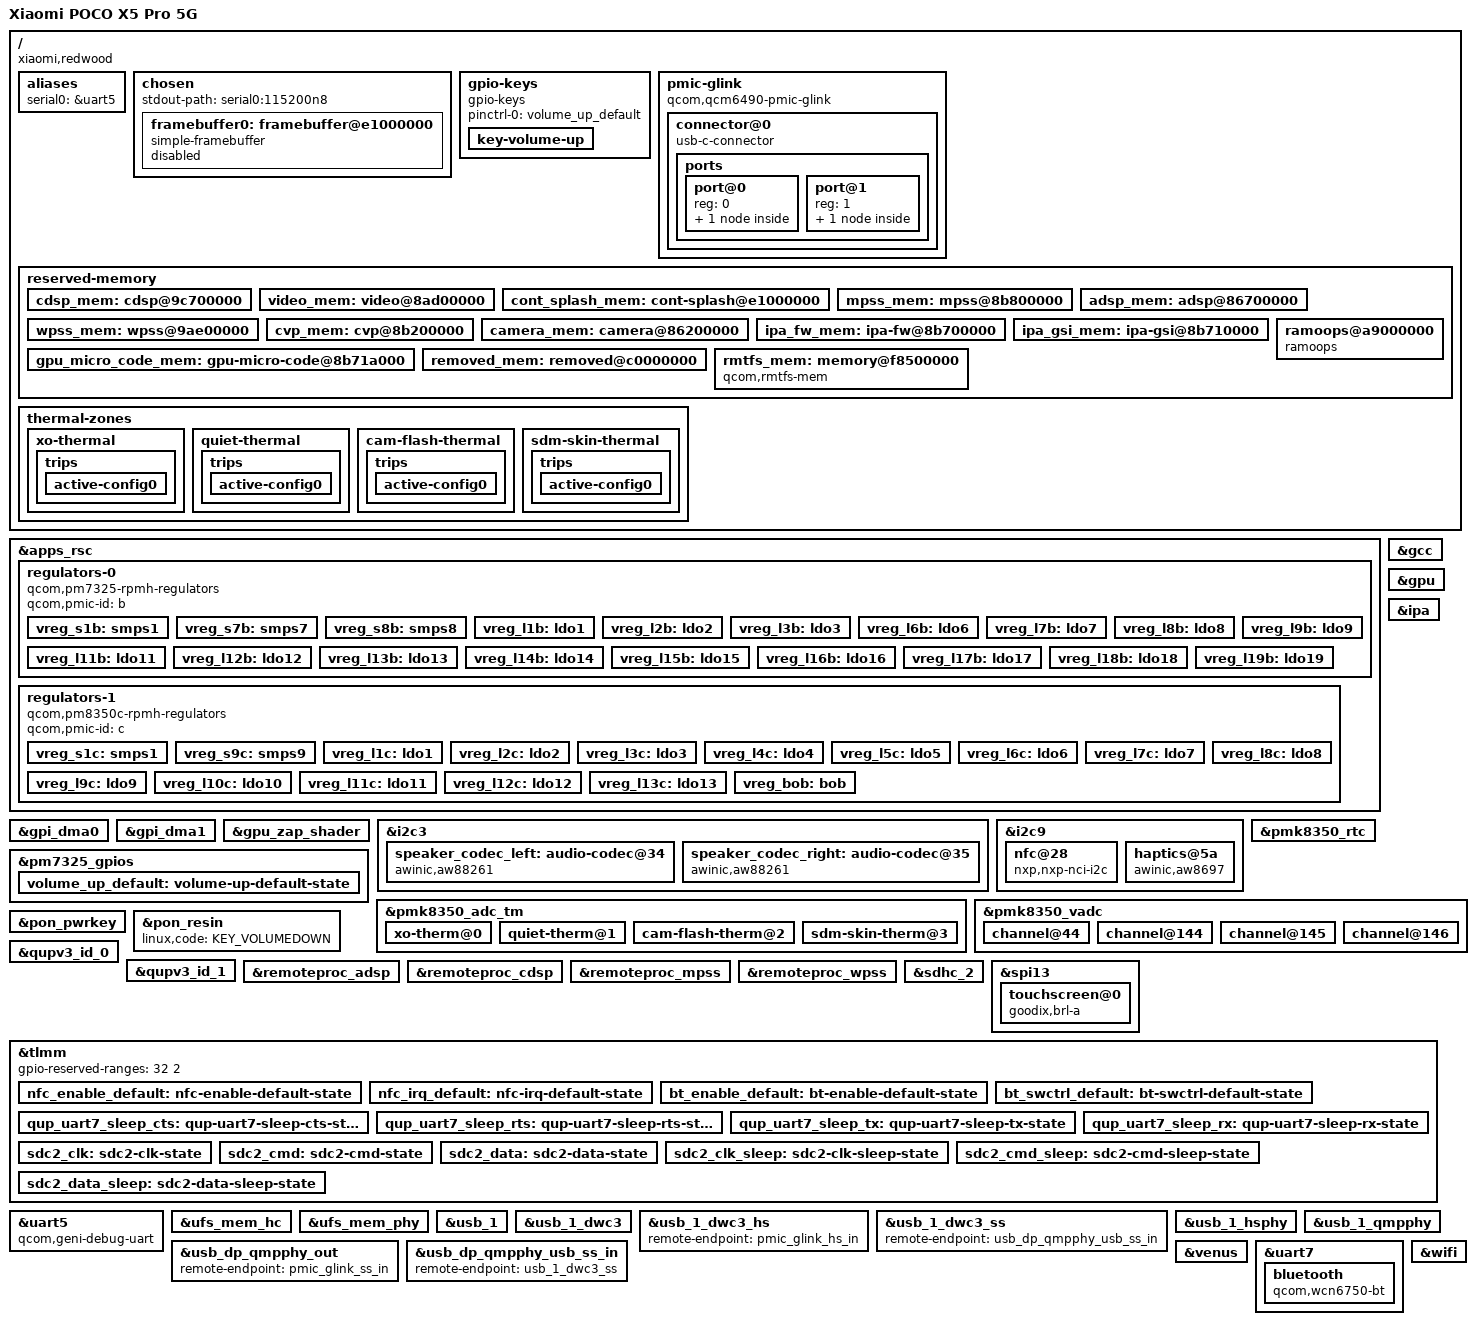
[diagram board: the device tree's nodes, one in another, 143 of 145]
// SPDX-License-Identifier: BSD-3-Clause
/*
 * Copyright (c) 2024, Gianluca Boiano
 *
 * Based on qcm6490-fairphone-fp5.dts
 */

/dts-v1/;

#include <dt-bindings/arm/qcom,ids.h>
#include <dt-bindings/gpio/gpio.h>
#include <dt-bindings/iio/qcom,spmi-adc7-pm7325.h>
#include <dt-bindings/iio/qcom,spmi-adc7-pmk8350.h>
#include <dt-bindings/input/input.h>
#include <dt-bindings/pinctrl/qcom,pmic-gpio.h>
#include <dt-bindings/regulator/qcom,rpmh-regulator.h>
#include "sc7280.dtsi"
#include "pm7325.dtsi"
#include "pm8350c.dtsi"
#include "pmk8350.dtsi"

/delete-node/ &rmtfs_mem;

/ {
	model = "Xiaomi POCO X5 Pro 5G";
	compatible = "xiaomi,redwood", "qcom,sm7325";
	chassis-type = "handset";

	/* SM7325 msm-id: 475 (0x1db) and 515 (0x203) */
	qcom,msm-id = <QCOM_ID_SM7325 0x10000>,
		      <QCOM_ID_SM7325P 0x10000>;
	qcom,board-id = <0x1000b 0x0>;

	aliases {
		serial0 = &uart5;
	};

	chosen {
		#address-cells = <2>;
		#size-cells = <2>;
		ranges;

		stdout-path = "serial0:115200n8";

		framebuffer0: framebuffer@e1000000 {
			compatible = "simple-framebuffer";
			reg = <0x0 0xe1000000 0x0 (1080 * 2400 * 4)>;
			width = <1080>;
			height = <2400>;
			stride = <(1080 * 4)>;
			format = "a8r8g8b8";
			status = "disabled";
		};
	};

	gpio-keys {
		compatible = "gpio-keys";

		pinctrl-0 = <&volume_up_default>;
		pinctrl-names = "default";

		key-volume-up {
			label = "Volume up";
			gpios = <&pm7325_gpios 6 GPIO_ACTIVE_LOW>;
			linux,code = <KEY_VOLUMEUP>;
			debounce-interval = <15>;
		};
	};

	pmic-glink {
		compatible = "qcom,qcm6490-pmic-glink", "qcom,pmic-glink";

		#address-cells = <1>;
		#size-cells = <0>;

		connector@0 {
			compatible = "usb-c-connector";
			reg = <0>;
			power-role = "dual";
			data-role = "dual";

			ports {
				#address-cells = <1>;
				#size-cells = <0>;

				port@0 {
					reg = <0>;

					pmic_glink_hs_in: endpoint {
						remote-endpoint = <&usb_1_dwc3_hs>;
					};
				};

				port@1 {
					reg = <1>;

					pmic_glink_ss_in: endpoint {
						remote-endpoint = <&usb_dp_qmpphy_out>;
					};
				};
			};
		};
	};

	reserved-memory {
		/* Override cdsp_mem from sc7280.dtsi with SM7325 address */
		/delete-node/ cdsp@88f00000;
		cdsp_mem: cdsp@9c700000 {
			reg = <0x0 0x9c700000 0x0 0x1e00000>;
			no-map;
		};

		/* Override video_mem from sc7280.dtsi with SM7325 address */
		/delete-node/ video@8b200000;
		video_mem: video@8ad00000 {
			reg = <0x0 0x8ad00000 0x0 0x500000>;
			no-map;
		};

		cont_splash_mem: cont-splash@e1000000 {
			reg = <0x0 0xe1000000 0x0 0x2300000>;
			no-map;
		};

		mpss_mem: mpss@8b800000 {
			reg = <0x0 0x8b800000 0x0 0xf600000>;
			no-map;
		};

		adsp_mem: adsp@86700000 {
			reg = <0x0 0x86700000 0x0 0x4000000>;
			no-map;
		};

		wpss_mem: wpss@9ae00000 {
			reg = <0x0 0x9ae00000 0x0 0x1900000>;
			no-map;
		};

		cvp_mem: cvp@8b200000 {
			reg = <0x0 0x8b200000 0x0 0x500000>;
			no-map;
		};

		camera_mem: camera@86200000 {
			reg = <0x0 0x86200000 0x0 0x500000>;
			no-map;
		};

		ipa_fw_mem: ipa-fw@8b700000 {
			reg = <0x0 0x8b700000 0x0 0x10000>;
			no-map;
		};

		ipa_gsi_mem: ipa-gsi@8b710000 {
			reg = <0x0 0x8b710000 0x0 0xa000>;
			no-map;
		};

		gpu_micro_code_mem: gpu-micro-code@8b71a000 {
			reg = <0x0 0x8b71a000 0x0 0x2000>;
			no-map;
		};

		removed_mem: removed@c0000000 {
			reg = <0x0 0xc0000000 0x0 0x6800000>;
			no-map;
		};

		rmtfs_mem: memory@f8500000 {
			compatible = "qcom,rmtfs-mem";
			reg = <0x0 0xf8500000 0x0 0x600000>;
			no-map;

			qcom,client-id = <1>;
			qcom,vmid = <QCOM_SCM_VMID_MSS_MSA>, <QCOM_SCM_VMID_NAV>;
		};

		ramoops@a9000000 {
			compatible = "ramoops";
			reg = <0x0 0xa9000000 0x0 0x200000>;
			pmsg-size = <0x200000>;
			console-size = <0x100000>;
		};
	};

	thermal-zones {
		xo-thermal {
			polling-delay-passive = <0>;
			polling-delay = <0>;
			thermal-sensors = <&pmk8350_adc_tm 0>;

			trips {
				active-config0 {
					temperature = <125000>;
					hysteresis = <1000>;
					type = "passive";
				};
			};
		};

		quiet-thermal {
			polling-delay-passive = <0>;
			polling-delay = <0>;
			thermal-sensors = <&pmk8350_adc_tm 1>;

			trips {
				active-config0 {
					temperature = <125000>;
					hysteresis = <1000>;
					type = "passive";
				};
			};
		};

		cam-flash-thermal {
			polling-delay-passive = <0>;
			polling-delay = <0>;
			thermal-sensors = <&pmk8350_adc_tm 2>;

			trips {
				active-config0 {
					temperature = <125000>;
					hysteresis = <1000>;
					type = "passive";
				};
			};
		};

		sdm-skin-thermal {
			polling-delay-passive = <0>;
			polling-delay = <0>;
			thermal-sensors = <&pmk8350_adc_tm 3>;

			trips {
				active-config0 {
					temperature = <125000>;
					hysteresis = <1000>;
					type = "passive";
				};
			};
		};
	};
};

&apps_rsc {
	regulators-0 {
		compatible = "qcom,pm7325-rpmh-regulators";
		qcom,pmic-id = "b";

		vreg_s1b: smps1 {
			regulator-min-microvolt = <1840000>;
			regulator-max-microvolt = <2040000>;
		};

		vreg_s7b: smps7 {
			regulator-min-microvolt = <535000>;
			regulator-max-microvolt = <1120000>;
		};

		vreg_s8b: smps8 {
			regulator-min-microvolt = <1200000>;
			regulator-max-microvolt = <1500000>;
			regulator-initial-mode = <RPMH_REGULATOR_MODE_RET>;
		};

		vreg_l1b: ldo1 {
			regulator-min-microvolt = <825000>;
			regulator-max-microvolt = <925000>;
			regulator-initial-mode = <RPMH_REGULATOR_MODE_HPM>;
		};

		vreg_l2b: ldo2 {
			regulator-min-microvolt = <2700000>;
			regulator-max-microvolt = <3544000>;
			regulator-initial-mode = <RPMH_REGULATOR_MODE_HPM>;
		};

		vreg_l3b: ldo3 {
			regulator-min-microvolt = <312000>;
			regulator-max-microvolt = <910000>;
			regulator-initial-mode = <RPMH_REGULATOR_MODE_HPM>;
		};

		vreg_l6b: ldo6 {
			regulator-min-microvolt = <1140000>;
			regulator-max-microvolt = <1260000>;
			regulator-initial-mode = <RPMH_REGULATOR_MODE_HPM>;
		};

		vreg_l7b: ldo7 {
			regulator-min-microvolt = <2952000>;
			regulator-max-microvolt = <2952000>;
			regulator-initial-mode = <RPMH_REGULATOR_MODE_HPM>;
		};

		vreg_l8b: ldo8 {
			regulator-min-microvolt = <870000>;
			regulator-max-microvolt = <970000>;
			regulator-initial-mode = <RPMH_REGULATOR_MODE_HPM>;
		};

		vreg_l9b: ldo9 {
			regulator-min-microvolt = <1200000>;
			regulator-max-microvolt = <1304000>;
			regulator-initial-mode = <RPMH_REGULATOR_MODE_HPM>;
		};

		vreg_l11b: ldo11 {
			regulator-min-microvolt = <1504000>;
			regulator-max-microvolt = <2000000>;
			regulator-initial-mode = <RPMH_REGULATOR_MODE_HPM>;
		};

		vreg_l12b: ldo12 {
			regulator-min-microvolt = <751000>;
			regulator-max-microvolt = <824000>;
			regulator-initial-mode = <RPMH_REGULATOR_MODE_HPM>;
		};

		vreg_l13b: ldo13 {
			regulator-min-microvolt = <530000>;
			regulator-max-microvolt = <824000>;
			regulator-initial-mode = <RPMH_REGULATOR_MODE_HPM>;
		};

		vreg_l14b: ldo14 {
			regulator-min-microvolt = <1080000>;
			regulator-max-microvolt = <1304000>;
			regulator-initial-mode = <RPMH_REGULATOR_MODE_HPM>;
		};

		vreg_l15b: ldo15 {
			regulator-min-microvolt = <765000>;
			regulator-max-microvolt = <1020000>;
			regulator-initial-mode = <RPMH_REGULATOR_MODE_HPM>;
		};

		vreg_l16b: ldo16 {
			regulator-min-microvolt = <1100000>;
			regulator-max-microvolt = <1300000>;
			regulator-initial-mode = <RPMH_REGULATOR_MODE_HPM>;
		};

		vreg_l17b: ldo17 {
			regulator-min-microvolt = <1700000>;
			regulator-max-microvolt = <1900000>;
			regulator-initial-mode = <RPMH_REGULATOR_MODE_HPM>;
		};

		vreg_l18b: ldo18 {
			regulator-min-microvolt = <1800000>;
			regulator-max-microvolt = <2000000>;
			regulator-initial-mode = <RPMH_REGULATOR_MODE_HPM>;
		};

		vreg_l19b: ldo19 {
			regulator-min-microvolt = <1800000>;
			regulator-max-microvolt = <2000000>;
			regulator-initial-mode = <RPMH_REGULATOR_MODE_HPM>;
		};
	};

	regulators-1 {
		compatible = "qcom,pm8350c-rpmh-regulators";
		qcom,pmic-id = "c";

		vreg_s1c: smps1 {
			regulator-min-microvolt = <2190000>;
			regulator-max-microvolt = <2210000>;
			regulator-initial-mode = <RPMH_REGULATOR_MODE_HPM>;
		};

		vreg_s9c: smps9 {
			regulator-min-microvolt = <1010000>;
			regulator-max-microvolt = <1170000>;
			regulator-initial-mode = <RPMH_REGULATOR_MODE_HPM>;
		};

		vreg_l1c: ldo1 {
			regulator-min-microvolt = <1800000>;
			regulator-max-microvolt = <1980000>;
			regulator-initial-mode = <RPMH_REGULATOR_MODE_HPM>;
		};

		vreg_l2c: ldo2 {
			regulator-min-microvolt = <1800000>;
			regulator-max-microvolt = <1950000>;
			regulator-initial-mode = <RPMH_REGULATOR_MODE_HPM>;
		};

		vreg_l3c: ldo3 {
			regulator-min-microvolt = <3000000>;
			regulator-max-microvolt = <3400000>;
			regulator-initial-mode = <RPMH_REGULATOR_MODE_HPM>;
		};

		vreg_l4c: ldo4 {
			regulator-min-microvolt = <1620000>;
			regulator-max-microvolt = <3300000>;
			regulator-initial-mode = <RPMH_REGULATOR_MODE_HPM>;
		};

		vreg_l5c: ldo5 {
			regulator-min-microvolt = <1620000>;
			regulator-max-microvolt = <3300000>;
			regulator-initial-mode = <RPMH_REGULATOR_MODE_HPM>;
		};

		vreg_l6c: ldo6 {
			regulator-min-microvolt = <1650000>;
			regulator-max-microvolt = <3544000>;
			regulator-initial-mode = <RPMH_REGULATOR_MODE_HPM>;
		};

		vreg_l7c: ldo7 {
			regulator-min-microvolt = <3000000>;
			regulator-max-microvolt = <3544000>;
			regulator-initial-mode = <RPMH_REGULATOR_MODE_HPM>;
		};

		vreg_l8c: ldo8 {
			regulator-min-microvolt = <1620000>;
			regulator-max-microvolt = <2000000>;
			regulator-initial-mode = <RPMH_REGULATOR_MODE_HPM>;
		};

		vreg_l9c: ldo9 {
			regulator-min-microvolt = <2700000>;
			regulator-max-microvolt = <3544000>;
			regulator-initial-mode = <RPMH_REGULATOR_MODE_HPM>;
		};

		vreg_l10c: ldo10 {
			regulator-min-microvolt = <720000>;
			regulator-max-microvolt = <1050000>;
			regulator-initial-mode = <RPMH_REGULATOR_MODE_HPM>;
		};

		vreg_l11c: ldo11 {
			regulator-min-microvolt = <2800000>;
			regulator-max-microvolt = <3544000>;
			regulator-initial-mode = <RPMH_REGULATOR_MODE_HPM>;
		};

		vreg_l12c: ldo12 {
			regulator-min-microvolt = <1650000>;
			regulator-max-microvolt = <2000000>;
			regulator-initial-mode = <RPMH_REGULATOR_MODE_HPM>;
		};

		vreg_l13c: ldo13 {
			regulator-min-microvolt = <2700000>;
			regulator-max-microvolt = <3544000>;
			regulator-initial-mode = <RPMH_REGULATOR_MODE_HPM>;
		};

		vreg_bob: bob {
			regulator-min-microvolt = <3008000>;
			regulator-max-microvolt = <3960000>;
			regulator-initial-mode = <RPMH_REGULATOR_MODE_AUTO>;
		};
	};
};

&gcc {
	protected-clocks = <GCC_CFG_NOC_LPASS_CLK>,
			   <GCC_EDP_CLKREF_EN>,
			   <GCC_MSS_CFG_AHB_CLK>,
			   <GCC_MSS_GPLL0_MAIN_DIV_CLK_SRC>,
			   <GCC_MSS_OFFLINE_AXI_CLK>,
			   <GCC_MSS_Q6SS_BOOT_CLK_SRC>,
			   <GCC_MSS_Q6_MEMNOC_AXI_CLK>,
			   <GCC_MSS_SNOC_AXI_CLK>,
			   <GCC_QSPI_CNOC_PERIPH_AHB_CLK>,
			   <GCC_QSPI_CORE_CLK>,
			   <GCC_QSPI_CORE_CLK_SRC>,
			   <GCC_SEC_CTRL_CLK_SRC>,
			   <GCC_WPSS_AHB_BDG_MST_CLK>,
			   <GCC_WPSS_AHB_CLK>,
			   <GCC_WPSS_RSCP_CLK>;
};

&gpi_dma0 {
	status = "okay";
};

&gpi_dma1 {
	status = "okay";
};

&gpu {
	status = "okay";
};

&gpu_zap_shader {
	firmware-name = "qcom/sm7325/xiaomi/redwood/a660_zap.mbn";
};

&i2c3 {
	status = "okay";

	/* Awinic AW882XX stereo amplifiers */
	speaker_codec_left: audio-codec@34 {
		compatible = "awinic,aw88261";
		reg = <0x34>;
		#sound-dai-cells = <0>;
		awinic,audio-channel = <1>;
		awinic,sync-flag;
	};

	speaker_codec_right: audio-codec@35 {
		compatible = "awinic,aw88261";
		reg = <0x35>;
		#sound-dai-cells = <0>;
		awinic,audio-channel = <0>;
		awinic,sync-flag;
	};
};

&i2c9 {
	status = "okay";

	/* NXP SN100/SN110 NFC Controller */
	nfc@28 {
		compatible = "nxp,nxp-nci-i2c";
		reg = <0x28>;

		interrupt-parent = <&tlmm>;
		interrupts = <41 IRQ_TYPE_LEVEL_HIGH>;

		enable-gpios = <&tlmm 38 GPIO_ACTIVE_HIGH>;
		firmware-gpios = <&tlmm 40 GPIO_ACTIVE_HIGH>;

		pinctrl-0 = <&nfc_enable_default>, <&nfc_irq_default>;
		pinctrl-names = "default";
	};

	/* Awinic AW8697 Haptic Motor */
	haptics@5a {
		compatible = "awinic,aw8697";
		reg = <0x5a>;

		interrupt-parent = <&tlmm>;
		interrupts = <18 IRQ_TYPE_LEVEL_LOW>;

		reset-gpios = <&tlmm 17 GPIO_ACTIVE_LOW>;

		awinic,mode = <0>;  /* RAM mode */
	};
};

&ipa {
	qcom,gsi-loader = "self";
	memory-region = <&ipa_fw_mem>;
	firmware-name = "qcom/sm7325/xiaomi/redwood/ipa_fws.mbn";
	status = "okay";
};

&pm7325_gpios {
	volume_up_default: volume-up-default-state {
		pins = "gpio6";
		function = PMIC_GPIO_FUNC_NORMAL;
		power-source = <1>;
		bias-pull-up;
		input-enable;
	};
};

&pmk8350_adc_tm {
	status = "okay";

	xo-therm@0 {
		reg = <0>;
		io-channels = <&pmk8350_vadc PMK8350_ADC7_AMUX_THM1_100K_PU>;
		qcom,ratiometric;
		qcom,hw-settle-time-us = <200>;
	};

	quiet-therm@1 {
		reg = <1>;
		io-channels = <&pmk8350_vadc PM7325_ADC7_AMUX_THM1_100K_PU>;
		qcom,ratiometric;
		qcom,hw-settle-time-us = <200>;
	};

	cam-flash-therm@2 {
		reg = <2>;
		io-channels = <&pmk8350_vadc PM7325_ADC7_AMUX_THM2_100K_PU>;
		qcom,ratiometric;
		qcom,hw-settle-time-us = <200>;
	};

	sdm-skin-therm@3 {
		reg = <3>;
		io-channels = <&pmk8350_vadc PM7325_ADC7_AMUX_THM3_100K_PU>;
		qcom,ratiometric;
		qcom,hw-settle-time-us = <200>;
	};
};

&pmk8350_rtc {
	status = "okay";
};

&pmk8350_vadc {
	status = "okay";

	channel@44 {
		reg = <PMK8350_ADC7_AMUX_THM1_100K_PU>;
		qcom,ratiometric;
		qcom,hw-settle-time = <200>;
		qcom,pre-scaling = <1 1>;
		label = "pmk8350_xo_therm";
	};

	channel@144 {
		reg = <PM7325_ADC7_AMUX_THM1_100K_PU>;
		qcom,ratiometric;
		qcom,hw-settle-time = <200>;
		qcom,pre-scaling = <1 1>;
		label = "pm7325_quiet_therm";
	};

	channel@145 {
		reg = <PM7325_ADC7_AMUX_THM2_100K_PU>;
		qcom,ratiometric;
		qcom,hw-settle-time = <200>;
		qcom,pre-scaling = <1 1>;
		label = "pm7325_cam_flash_therm";
	};

	channel@146 {
		reg = <PM7325_ADC7_AMUX_THM3_100K_PU>;
		qcom,ratiometric;
		qcom,hw-settle-time = <200>;
		qcom,pre-scaling = <1 1>;
		label = "pm7325_sdm_skin_therm";
	};
};

&pon_pwrkey {
	status = "okay";
};

&pon_resin {
	linux,code = <KEY_VOLUMEDOWN>;
	status = "okay";
};

&qupv3_id_0 {
	status = "okay";
};

&qupv3_id_1 {
	status = "okay";
};

&remoteproc_adsp {
	firmware-name = "qcom/sm7325/xiaomi/redwood/adsp.mbn";
	status = "okay";
};

&remoteproc_cdsp {
	firmware-name = "qcom/sm7325/xiaomi/redwood/cdsp.mbn";
	status = "okay";
};

&remoteproc_mpss {
	firmware-name = "qcom/sm7325/xiaomi/redwood/modem.mbn";
	status = "okay";
};

&remoteproc_wpss {
	firmware-name = "qcom/sm7325/xiaomi/redwood/wpss.mbn";
	status = "okay";
};

&sdhc_2 {
	vmmc-supply = <&vreg_l9c>;
	vqmmc-supply = <&vreg_l6c>;

	pinctrl-0 = <&sdc2_clk>, <&sdc2_cmd>, <&sdc2_data>;
	pinctrl-1 = <&sdc2_clk_sleep>, <&sdc2_cmd_sleep>, <&sdc2_data_sleep>;

	status = "okay";
};

&spi13 {
	status = "okay";

	/* Goodix GT9916 touchscreen */
	touchscreen@0 {
		compatible = "goodix,brl-a";
		reg = <0>;
		spi-max-frequency = <1000000>;

		goodix,avdd-name = "avdd";
		avdd-supply = <&vreg_l3c>;
		goodix,iovdd-name = "iovdd";
		iovdd-supply = <&vreg_l8c>;

		goodix,irq-gpio = <&tlmm 81 0x0>;
		goodix,irq-flags = <2>; /* trigger falling */
		goodix,reset-gpio = <&tlmm 105 0x0>;

		goodix,panel-max-x = <1080>;
		goodix,panel-max-y = <2400>;
		goodix,panel-max-w = <255>;

		goodix,firmware-name = "goodix_firmware_redwood.bin";
		goodix,config-name = "goodix_cfg_group_redwood.bin";
	};
};

&tlmm {
	gpio-reserved-ranges = <32 2>;

	nfc_enable_default: nfc-enable-default-state {
		pins = "gpio38";
		function = "gpio";
		drive-strength = <2>;
		bias-disable;
		output-low;
	};

	nfc_irq_default: nfc-irq-default-state {
		pins = "gpio41";
		function = "gpio";
		drive-strength = <2>;
		bias-pull-down;
	};

	bt_enable_default: bt-enable-default-state {
		pins = "gpio85";
		function = "gpio";
		output-low;
		bias-disable;
	};

	bt_swctrl_default: bt-swctrl-default-state {
		pins = "gpio86";
		function = "gpio";
		bias-pull-down;
	};

	qup_uart7_sleep_cts: qup-uart7-sleep-cts-state {
		pins = "gpio28";
		function = "gpio";
		bias-bus-hold;
	};

	qup_uart7_sleep_rts: qup-uart7-sleep-rts-state {
		pins = "gpio29";
		function = "gpio";
		bias-pull-down;
	};

	qup_uart7_sleep_tx: qup-uart7-sleep-tx-state {
		pins = "gpio30";
		function = "gpio";
		bias-pull-up;
	};

	qup_uart7_sleep_rx: qup-uart7-sleep-rx-state {
		pins = "gpio31";
		function = "gpio";
		bias-pull-up;
	};

	sdc2_clk: sdc2-clk-state {
		pins = "sdc2_clk";
		drive-strength = <16>;
		bias-disable;
	};

	sdc2_cmd: sdc2-cmd-state {
		pins = "sdc2_cmd";
		drive-strength = <10>;
		bias-pull-up;
	};

	sdc2_data: sdc2-data-state {
		pins = "sdc2_data";
		drive-strength = <10>;
		bias-pull-up;
	};

	sdc2_clk_sleep: sdc2-clk-sleep-state {
		pins = "sdc2_clk";
		drive-strength = <2>;
		bias-disable;
	};

	sdc2_cmd_sleep: sdc2-cmd-sleep-state {
		pins = "sdc2_cmd";
		drive-strength = <2>;
		bias-pull-up;
	};

	sdc2_data_sleep: sdc2-data-sleep-state {
		pins = "sdc2_data";
		drive-strength = <2>;
		bias-pull-up;
	};

};

&uart5 {
	compatible = "qcom,geni-debug-uart";
	status = "okay";
};

&ufs_mem_hc {
	reset-gpios = <&tlmm 175 GPIO_ACTIVE_LOW>;

	vcc-supply = <&vreg_l7b>;
	vcc-max-microamp = <800000>;
	vccq-supply = <&vreg_l9b>;
	vccq-max-microamp = <900000>;

	status = "okay";
};

&ufs_mem_phy {
	vdda-phy-supply = <&vreg_l10c>;
	vdda-pll-supply = <&vreg_l6b>;

	status = "okay";
};

&usb_1 {
	status = "okay";
};

&usb_1_dwc3 {
	dr_mode = "otg";
	usb-role-switch;
	maximum-speed = "super-speed";
};

&usb_1_dwc3_hs {
	remote-endpoint = <&pmic_glink_hs_in>;
};

&usb_1_dwc3_ss {
	remote-endpoint = <&usb_dp_qmpphy_usb_ss_in>;
};

&usb_1_hsphy {
	vdda-pll-supply = <&vreg_l10c>;
	vdda18-supply = <&vreg_l1c>;
	vdda33-supply = <&vreg_l2b>;

	/* Tuning parameters from downstream */
	qcom,hs-crossover-voltage-microvolt = <28000>;
	qcom,hs-output-impedance-micro-ohms = <2600000>;
	qcom,hs-rise-fall-time-bp = <5430>;
	qcom,hs-disconnect-bp = <1743>;
	qcom,hs-amplitude-bp = <2430>;

	status = "okay";
};

&usb_1_qmpphy {
	vdda-phy-supply = <&vreg_l6b>;
	vdda-pll-supply = <&vreg_l1b>;

	orientation-switch;

	status = "okay";
};

&usb_dp_qmpphy_out {
	remote-endpoint = <&pmic_glink_ss_in>;
};

&usb_dp_qmpphy_usb_ss_in {
	remote-endpoint = <&usb_1_dwc3_ss>;
};

&venus {
	firmware-name = "qcom/sm7325/xiaomi/redwood/venus.mbn";
	status = "okay";
};

&uart7 {
	/delete-property/ interrupts;
	interrupts-extended = <&intc GIC_SPI 608 IRQ_TYPE_LEVEL_HIGH>,
			      <&tlmm 31 IRQ_TYPE_EDGE_FALLING>;

	pinctrl-1 = <&qup_uart7_sleep_cts>, <&qup_uart7_sleep_rts>,
		    <&qup_uart7_sleep_tx>, <&qup_uart7_sleep_rx>;
	pinctrl-names = "default", "sleep";

	status = "okay";

	bluetooth {
		compatible = "qcom,wcn6750-bt";

		pinctrl-0 = <&bt_enable_default>, <&bt_swctrl_default>;
		pinctrl-names = "default";

		enable-gpios = <&tlmm 85 GPIO_ACTIVE_HIGH>;
		swctrl-gpios = <&tlmm 86 GPIO_ACTIVE_HIGH>;

		vddio-supply = <&vreg_l19b>;
		vddaon-supply = <&vreg_s7b>;
		vddbtcxmx-supply = <&vreg_s7b>;
		vddrfacmn-supply = <&vreg_s7b>;
		vddrfa0p8-supply = <&vreg_s7b>;
		vddrfa1p7-supply = <&vreg_s1b>;
		vddrfa1p2-supply = <&vreg_s8b>;
		vddrfa2p2-supply = <&vreg_s1c>;
		vddasd-supply = <&vreg_l11c>;

		max-speed = <3200000>;
	};
};

&wifi {
	qcom,ath11k-calibration-variant = "Xiaomi_Redwood";
	status = "okay";
};
